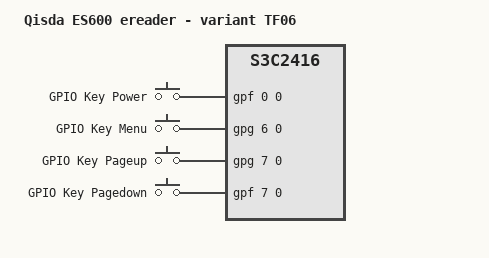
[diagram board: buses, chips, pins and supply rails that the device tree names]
/*
 * Qisda ES600 ereader - variant TF06
 *
 * Copyright (c) 2012 Heiko Stuebner <heiko@sntech.de>
 *
 * This program is free software; you can redistribute it and/or modify
 * it under the terms of the GNU General Public License version 2 as
 * published by the Free Software Foundation.
*/

/dts-v1/;
/include/ "s3c2450.dtsi"
/include/ "s3c2416-common-es600.dtsi"

/ {
	model = "Qisda ES600 ereader - variant TF06";
	compatible = "qisda,tf06", "samsung,s3c2450", "samsung,s3c2416";

//	chosen {
//		bootargs = "root=/dev/ram0 rw ramdisk=8192 console=ttySAC1,115200";
//	};

	gpio-keys {
		compatible = "gpio-keys";
		#address-cells = <1>;
		#size-cells = <0>;
		autorepeat;

		button@0 {
			gpios = <&gpf 0 0 0x10003>;
			linux,code = <116>;
			label = "GPIO Key Power";
			linux,input-type = <1>;
			gpio-key,wakeup = <1>;
			debounce-interval = <100>;
		};
		button@1 {
			gpios = <&gpg 6 0 0x10003>;
			linux,code = <139>;
			label = "GPIO Key Menu";
			linux,input-type = <1>;
			gpio-key,wakeup = <0>;
			debounce-interval = <100>;
		};
		button@2 {
			gpios = <&gpg 7 0 0x10003>;
			linux,code = <104>;
			label = "GPIO Key Pageup";
			linux,input-type = <1>;
			gpio-key,wakeup = <0>;
			debounce-interval = <100>;
		};
		button@3 {
			gpios = <&gpf 7 0 0x10003>;
			linux,code = <109>;
			label = "GPIO Key Pagedown";
			linux,input-type = <1>;
			gpio-key,wakeup = <0>;
			debounce-interval = <100>;
		};
	};

	es600-epd@4C800000 {
		compatible = "es600-epd";
		reg = <0x4C800000 0x4000>;
		driver = "auo_k1901fb";
		resolution = <0>;
		quirks = <2>; /* standby broken */
		fps = <4>;
		gpios = <&gpd 9 1 0>,	/* nrst */
			<&gpb 2 0 0>,	/* nbusy */
			<&gpb 1 1 0>;	/* nsleep */
	};
};
